# LIN_LIN_52400000h register map
Vendor: Texas Instruments
Peripheral module from a debugger description file (folder AM263P).
Registers are 32-bit, read-write, reset 0x0 unless marked. A register's access mark holds for its fields unless they carry their own. Offsets are as the file gives them; lines under a group give offsets from that group; [hi:lo] are bit positions; {n}, {i} and the like mark numbered series; 'fields as' and 'values as' point back to an identical list; <NAME> marks a mode.

## LIN (part 1 of 2)
0x00 LIN_SCIGCR0 — The SCIGCR0 register defines the module reset.
  [0] RESET — This bit resets the SCI/LIN module. This bit is effective in LIN or SCI-compatible mode.. This bit affects the reset state of the SCI/LIN module. 0 SCI/LIN module is in held in reset.1 SCI/LIN module is out of reset.
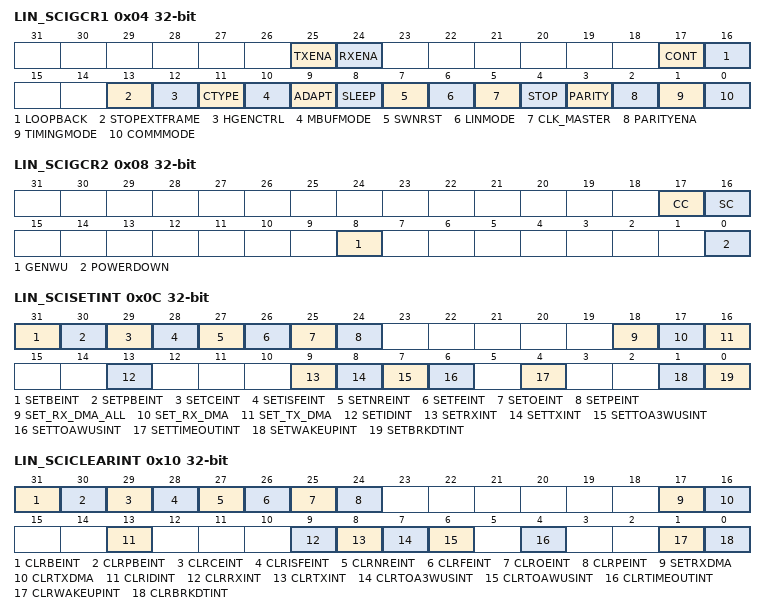
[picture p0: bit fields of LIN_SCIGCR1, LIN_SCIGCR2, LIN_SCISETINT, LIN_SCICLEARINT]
0x04 LIN_SCIGCR1 — The SCIGCR1 register defines the frame format, protocol, and communication mode used by the SCI.
  [25] TXENA — Transmit enable.This bit is effective in LIN and SCI modes. Data is transferred from SCITD or the TDy [with y=0, 1,...7] buffers in LIN mode to the SCITXSHF shift out register only when the TXENA bit is set. Note: Data written to SCITD or the transmit multi-buffer before TXENA is set is nottransmitted. If TXENA is cleared while transmission is ongoing, the data previouslywritten to SCITD is sent [including the checksum byte in LIN mode]. 0 Disable transfers from SCITD or TDy to SCITXSHF1 Enable transfers of data from SCITD or TDy to SCITXSHF
  [24] RXENA — Receive enable.This bit is effective in LIN or SCI-compatible mode. RXENA allows or prevents the transfer of data from SCIRXSHF to SCIRD or the receive multibuffers. Note: Clearing RXENA stops received characters from being transferred into the receive buffer or multi-buffers, prevents the RX status flags [see Table 7] from being updated by receive data, and inhibits both receive and error interrupts. However, the shift register continues to assemble data regardless of the state of RXENA. Note: If RXENA is cleared before the time the reception of a frame is complete, the data from the frame is not transferred into the receive buffer. Note: If RXENA is set before the time the reception of a frame is complete, the data from the frame is transferred into the receive buffer. If RXENA is set while SCIRXSHF is in the process of assembling a frame, the status flags are not guaranteed to be accurate for that frame. To ensure that the status flags correctly reflect what was detected on the bus during a particular frame, RXENA should be set before the detection of that frame 0 Prevents the receiver from transferring data from the shift buffer to the receive buffer or multi-buffers1 Allows the receiver to transfer data from the shift buffer to the receive buffer or multi-buffers
  [17] CONT — Continue on suspend.This bit has an effect only when a program is being debugged with an emulator, and it determines how the SCI/LIN operates when the program is suspended. This bit affects the LIN counters. When this bit is set, the counters are not stopped during debug. When this bit is cleared, the counters are stopped during debug. 0 When debug mode is entered, the SCI/LIN state machine is frozen. Transmissions and LIN counters are halted and resume when debug mode is exited.1 When debug mode is entered, the SCI/LIN continues to operate until the current transmit and receive functions are complete.
  [16] LOOPBACK — Loopback bit.This bit is effective in LIN or SCI-compatible mode. The self-checking option for the SCI/LIN can be selected with this bit. If the LINTX and LINRX pins are configured with SCI/LIN functionality, then the LINTX pin is internally connected to the LINRX pin. Externally, during loop back operation, the LINTX pin outputs a high value and the LINRX pin is in a high-impedance state. If this bit value is changed while the SCI/LIN is transmitting or receiving data, errors may result. 0 Loopback mode is disabled.1 Loopback mode is enabled.
  [13] STOPEXTFRAME — Stop extended frame communication.This bit is effective in LIN mode only. This bit can be written only during extended frame communication. When the extended frame communication is stopped, this bit is cleared automatically. 0 No effect1 Extended frame communication will be stopped, once current frame transmission/reception is completed.
  [12] HGENCTRL — HGEN control bit.This bit is effective in LIN mode only. This bit controls the type of mask filtering comparison. 0 ID filtering using ID-Byte. RECEIVEDID and IDBYTE fields in the LINID register are used for detecting a match (using TX/RXMASK values). Mask of 0xFF in LINMASK register will result in NO match.1 ID filtering using ID-SlaveTask byte (Recommended). RECEIVEDID and IDSLAVETASKBYTE fields in the LINID register are used for detecting a match (using TX/RXMASK values). Mask of 0xFF in LINMASK register will result in ALWAYS match
  [11] CTYPE — Checksum type.This bit is effective in LIN mode only. This bit controls the type of checksum to be used: classic or enhanced. 0 Classic checksum is used. This checksum is compatible with LIN 1.3 slave nodes. The classic checksum contains the modulo-256 sum with carry over all data bytes. Frames sent with Identifier 60 (0x3C) to 63 (0x3F) must allways use the classic checksum.1 Enhanced checksum is used. The enhanced checksum is compatible with LIN 2.0 and newer slave nodes. The enhanced checksum contains the modulo-256 sum with carry over all data bytes AND the protected Identifier.
  [10] MBUFMODE — Multibuffer mode.This bit is effective in LIN or SCI-compatible mode. This bit controls receive/transmit buffer usage, that is, whether the RX/TX multibuffers are used or a single register, RD0/TD0, is used. 0 The multi-buffer mode is disabled.1 The multi-buffer mode is enabled.
  [9] ADAPT — Adapt mode enable.This mode is effective in LIN mode only. This bit has an effect during the detection of the Sync Field. There are two LIN protocol bit rate modes that could be enabled with this bit according to the Node capability file definition: automatic or select. Software and network configuration will decide which of the previous two modes. When this bit is cleared, the LIN 2.0 protocol fixed bit rate should be used. If the ADAPT bit is set, a LIN target node detecting the baudrate will compare it to the prescalers in BRSR register and update it if they are different. The BRSR register will be updated with the new value. If this bit is not set there will be no adjustment to the BRSR register. This field is writable in LIN mode only. 0 Automatic baudrate adjustment is disabled.1 Automatic baudrate adjustment is enabled.
  [8] SLEEP — SCI sleep.SCI compatibility mode only. In a multiprocessor configuration, this bit controls the receive sleep function. Clearing this bit brings the SCI out of sleep mode. The receiver still operates when the SLEEP bit is set; however, RXRDY is updated and SCIRD is loaded with new data only when an address frame is detected. The remaining receiver status flags are updated and an error interrupt is requested if the corresponding interrupt enable bit is set, regardless of the value of the SLEEP bit. In this way, if an error is detected on the receive data line while the SCI is asleep, software can promptly deal with the error condition. The SLEEP bit is not automatically cleared when an address byte is detected. This field is writable in SCI mode only. 0 Sleep mode is disabled.1 Sleep mode is enabled.
  [7] SWNRST — Software reset [active low].This bit is effective in LIN or SCI-compatible mode. The SCI/LIN should only be configured while SWnRST = 0. Only the following configuration bits can be changed in runtime [i.e.,while SWnRESET = 1]:- STOP EXT Frame [SCIGCR1[13]]- CC bit [SCIGCR2[17]]- SC bit [SCIGCR2[16]] 0 The SCI/LIN is in its reset state; no data will be transmitted or received. Writing a 0 to this bit intializes the SCI/LIN state machines and operating flags. All affected logic is held in the reset state until a 1 is written to this bit.1 The SCI/LIN is in its ready state; transmission and reception can occur. After this bit is set to 1, the configuration of the module should not change.
  [6] LINMODE — LIN modeThis bit controls the mode of operation of the module. 0 LIN mode is disabled; SCI compatibility mode is enabled.1 LIN mode is enabled; SCI compatibility mode is disabled.
  [5] CLK_MASTER — SCI internal clock enable or LIN Master/Target configuration.In the SCI mode, this bit enables the clock to the SCI module. In LIN mode, this bit determines whether a LIN node is a target or master. 0 SCI-compatible mode: Reserved.LIN mode: The module is in slave mode.1 SCI-compatible mode: Enable clock to the SCI module.LIN mode: The node is in master mode.
  [4] STOP — SCI number of stop bits.This bit is effective in SCI-compatible mode only. Note: The receiver checks for only one stop bit. However in idle-line mode, the receiver waits until the end of the second stop bit [if STOP = 1] to begin checking for an idle period. This field is writable in SCI mode only. 0 One stop bit is used.1 Two stop bits are used.
  [3] PARITY — SCI parity odd/even selection.This bit is effective in SCI-compatible mode only. If the PARITY ENA bit [SCIGCR1.2] is set, PARITY designates odd or even parity. The parity bit is calculated based on the data bits in each frame and the address bit [in address-bit mode]. The start and stop fields in the frame are not included in the parity calculation. This field is writable in SCI mode only. 0 Odd parity is used. The SCI transmits and expects to receive a value in the parity bit that makes odd the total number of bits in the frame with the value of 1.1 Even parity is used. The SCI transmits and expects to receive a value in the parity bit that makes even the total number of bits in the frame with the value of 1.
  [2] PARITYENA — Parity enable.Enables or disables the parity function. 0 SCI-compatible mode: Parity disabled; no parity bit is generated during transmission or is expected during reception.LIN mode: ID-parity verification is disabled.1 SCI compatible mode: Parity enabled. A parity bit is generated during transmission and is expected during reception.LIN mode: ID-parity verification is enabled.
  [1] TIMINGMODE — SCI timing mode bit.This bit is effective in SCI-compatible mode only. It must be set to 1 when the SCI mode is used. This bit configures the SCI for asynchronous operation. 0 Reserved.1 Must be set to 1 when module is configured for SCI operation
  [0] COMMMODE — SCI/LIN communication mode bit.In compatibility mode, it selects the SCI communication mode. In LIN mode it selects length control option for ID-field bits ID4 and ID5. 0 SCI-compatible mode: Idle-line mode is used.LIN mode: ID4 and ID5 are not used for length control.1 SCI-compatible mode: Address-bit mode is used.LIN mode: ID4 and ID5 are used for length control.
0x08 LIN_SCIGCR2 — The SCIGCR2 register is used to send or compare a checksum byte during extended frames, to generate a wakeup and for low-power mode control of the LIN module.
  [17] CC — Compare Checksum.This mode is effective in LIN mode only. This bit is used by the receiver for extended frames to trigger a checksum compare. The user will initiate this transaction by Writing a one to this bit.In non multibuffer mode, once the CC bit is set, the checksum will be compared on the byte that is currently being received, expected to be the checkbyte.During Multi-buffer mode, following are the scenarios associated with the CC bit :- If CC bit is set during the reception of the data, then the byte that is received after the reception of the programmed no. of data bytes indicated by SCIFORMAT[18:16], is treated as a checksum byte.- If CC bit is set during the IDLE period [i.e. during inter-frame space], then the next immediate byte will be treated as a checksum byte. A CE will immediatly be flagged if there is a checksum error. This bit is automatically cleared once the checksum is successfully compared. 0 No effect1 Compare checksum on expected checkbyte
  [16] SC — Send ChecksumThis mode is effective in LIN mode only. This bit is used by the transmitter with extended frames to send a checkbyte. In non multibuffer mode the checkbyte will be sent after the current byte transmission. In multibuffer mode the checkbyte will be sent after the last byte count, indicated by the SCIFORMAT[18:16]]. This field is writable in LIN mode only. 0 No checkbyte will be sent.1 A checkbyte will be sent. This bit will automatically get cleared after the checkbyte is transmitted. The checksum will not be sent if this bit is set before transmitting the very first byte, that is, during interframe space.
  [8] GENWU — Generate wakeup signal.This bit controls the generation of a wakeup signal, by transmitting the TDO buffer value. This bit is cleared on reception of a valid sync break. 0 No effect1 Transmit TDO for wakeup. This bit will be cleared on a SWnRST (SCIGCR1.7)
  [0] POWERDOWN — Power down.This bit is effective in LIN or SCI-compatible mode. When the powerdown bit is set, the SCI/LIN module attempts to enter local low-power mode. If the POWERDOWN bit is set while the receiver is actively receiving data and the wakeup interrupt is disabled, then the SCI/LIN will delay low-power mode from being entered until completion of reception. In LIN mode the user may set the POWERDOWN bit on Sleep Command reception or on idle bus detection [more than 4 seconds, i.e. 80,000 cycles at 20kHz] 0 Normal operation1 Request local low-power mode
0x0C LIN_SCISETINT access not given — The SCISETINT register is used to enable the various interrupts available in the LIN module.
  [31] SETBEINT — Set bit error interrupt.This bit is effective in LIN mode only. Setting this bit enables the SCI/LIN module to generate an interrupt when there is a bit error. This field is writable in LIN mode only. 0 Interrupt is disabled. Writing a 0 to this bit has no effect.1 Interrupt is enabled. (access R/W1TS)
  [30] SETPBEINT — Set physical bus error interrupt.This bit is effective in LIN mode only. Setting this bit enables the SCI/LIN module to generate an interrupt when a physical bus error occurs. This field is writable in LIN mode only. 0 Interrupt is disabled. Writing a 0 to this bit has no effect.1 Interrupt is enabled. (access R/W1TS)
  [29] SETCEINT — Set checksum-error Interrupt.This bit is effective in LIN mode only. Setting this bit enables the SCI/LIN module to generate an interrupt when there is a checksum error. This field is writable in LIN mode only. 0 Interrupt is disabled. Writing a 0 to this bit has no effect.1 Interrupt is enabled. (access R/W1TS)
  [28] SETISFEINT — Set inconsistent-sync-field-error interrupt.This bit is effective in LIN mode only. Setting this bit enables the SCI/LIN module to generate an interrupt when there is an inconsistent sync field error. This field is writable in LIN mode only. 0 Interrupt is disabled. Writing a 0 to this bit has no effect.1 Interrupt is enabled. (access R/W1TS)
  [27] SETNREINT — Set no-response-error interrupt.This bit is effective in LIN mode only. Setting this bit enables the SCI/LIN module to generate an interrupt when a no-response error occurs. This field is writable in LIN mode only. 0 Interrupt is disabled. Writing a 0 to this bit has no effect.1 Interrupt is enabled. (access R/W1TS)
  [26] SETFEINT — Set framing-error interrupt.This bit is effective in LIN or SCI-compatible mode. Setting this bit enables the SCI/LIN module to generate an interrupt when a framing error occurs. 0 Interrupt is disabled. Writing a 0 to this bit has no effect.1 Interrupt is enabled. (access R/W1TS)
  [25] SETOEINT — Set overrun-error interrupt.This bit is effective in LIN or SCI-compatible mode. Setting this bit enables the SCI/LIN module to generate an interrupt when an overrun error occurs. 0 Interrupt is disabled. Writing a 0 to this bit has no effect.1 Interrupt is enabled. (access R/W1TS)
  [24] SETPEINT — Set parity interrupt.This bit is effective in LIN or SCI-compatible mode. Setting this bit enables the SCI/LIN module to generate an interrupt when a parity error occurs. 0 Interrupt is disabled. Writing a 0 to this bit has no effect.1 Interrupt is enabled. (access R/W1TS)
  [18] SET_RX_DMA_ALL — Set receiver DMA for Address & Data frames.This bit is effective in LIN or SCI-compatible mode. To enable RX DMA request for address and data frames this bit must be set. If it is cleared, RX interrupt request is generated for address frames and DMA requests are generated for data frames. 0 Receiver DMA request is disabled for address frames (RX interrupt request is enabled for address frames). Writing a 0 to this bit has no effect.1 Receiver DMA request is enabled for address and data frames (access R/W1TS)
  [17] SET_RX_DMA — Set receiver DMA.This bit is effective in LIN or SCI-compatible mode. To enable DMA requests for the receiver this bit must be set. If it is cleared, interrupt requests are generated depending on SETRXINT. 0 Receiver DMA request is disabled. Writing a 0 to this bit has no effect.1 Receiver DMA request is enabled. (access R/W1TS)
  [16] SET_TX_DMA — Set transmit DMA.This bit is effective in LIN or SCI-compatible mode. To enable DMA requests for the transmitter, this bit must be set. If it is cleared, interrupt requests are generated depending on SETTXINT. 0 Transmit DMA request is disabled. Writing a 0 to this bit has no effect.1 Transmit DMA request is enabled (access R/W1TS)
  [13] SETIDINT — Set Identification interrupt.This bit is effective in LIN mode only. This bit is set to enable interrupt once a valid matching identifier is received. 0 Interrupt is disabled. Writing a 0 to this bit has no effect.1 Interrupt is enabled. (access R/W1TS)
  [9] SETRXINT — Set Receiver interrupt.Setting this bit enables the SCI/LIN to generate a receive interrupt after a frame has been completely received and the data is being transferred from SCIRXSHF to SCIRD. 0 Interrupt is disabled. Writing a 0 to this bit has no effect.1 Interrupt is enabled. (access R/W1TS)
  [8] SETTXINT — Set Transmitter interrupt.Setting this bit enables the SCI/LIN to generate a transmit interrupt as data is being transferred from SCITD to SCITXSHF and the TXRDY bit is being set. 0 Interrupt is disabled. Writing a 0 to this bit has no effect.1 Interrupt is enabled. (access R/W1TS)
  [7] SETTOA3WUSINT — Set Timeout After 3 Wakeup Signals interrupt.This bit is effective in LIN mode only. Setting this bit enables the SCI/LIN to generate an interrupt when there is a timeout after 3 wakeup signals have been sent. This field is writable in LIN mode only. 0 Interrupt is disabled. Writing a 0 to this bit has no effect.1 Interrupt is enabled. (access R/W1TS)
  [6] SETTOAWUSINT — Set Timeout After Wakeup Signal interrupt.This bit is effective in LIN mode only. Setting this bit enables the SCI/LIN to generate an interrupt when there is a timeout after one wakeup signal has been sent. This field is writable in LIN mode only. 0 Interrupt is disabled. Writing a 0 to this bit has no effect.1 Interrupt is enabled. (access R/W1TS)
  [4] SETTIMEOUTINT — Set timeout interrupt.This bit is effective in LIN mode only. Setting this bit enables the SCI/LIN to generate an interrupt when no LIN bus activity [bus idle] occurs for at least 4 seconds. This field is writable in LIN mode only. 0 Interrupt is disabled. Writing a 0 to this bit has no effect.1 Interrupt is enabled. (access R/W1TS)
  [1] SETWAKEUPINT — Set wake-up interrupt.This bit is effective in LIN or SCI-compatible mode. Setting this bit enables the SCI/LIN to generate a wake-up interrupt and thereby exit low-power mode. The wake-up interrupt is asserted on falling edge of the wake-up pulse. If enabled, the wake-up interrupt is asserted when local low-power mode is requested while the receiver is busy or if a low level is detected on the SCIRX pin during low-power mode. Wake-up interrupt is not asserted upon a wakeup pulse if the module is not in power down mode. 0 Interrupt is disabled. Writing a 0 to this bit has no effect.1 Interrupt is enabled. (access R/W1TS)
  [0] SETBRKDTINT — Set break-detect interrupt.This bit is effective in SCI-compatible mode only. Setting this bit enables the SCI/LIN to generate an interrupt if a break condition is detected on the LINRX pin. This field is writable in SCI mode only. 0 Interrupt is disabled. Writing a 0 to this bit has no effect.1 Interrupt is enabled. (access R/W1TS)
0x10 LIN_SCICLEARINT access not given — The SCICLEARINT register is used to disable the enabled interrupts without accessing the SCISETINT register.
  [31] CLRBEINT — Clear Bit Error Interrupt.This bit is effective in LIN mode only. Setting this bit disables the bit error interrupt. This field is writable in LIN mode only. 0 Interrupt is disabled. Writing a 0 to this bit has no effect.1 Interrupt is enabled. Writing a 1 to this bit will disable the interrupt and clear this bit. (access R/W1TC)
  [30] CLRPBEINT — Clear Physical Bus Error Interrupt.This bit is effective in LIN mode only. Setting this bit disables the physical-bus error interrupt. This field is writable in LIN mode only. 0 Interrupt is disabled. Writing a 0 to this bit has no effect.1 Interrupt is enabled. Writing a 1 to this bit will disable the interrupt and clear this bit. (access R/W1TC)
  [29] CLRCEINT — Clear checksum-error Interrupt.This bit is effective in LIN mode only. Setting this bit disables the checksum-error interrupt. This field is writable in LIN mode only. 0 Interrupt is disabled. Writing a 0 to this bit has no effect.1 Interrupt is enabled. Writing a 1 to this bit will disable the interrupt and clear this bit. (access R/W1TC)
  [28] CLRISFEINT — Clear Inconsistent-Sync-Field-Error Interrupt.This bit is effective in LIN mode only. Setting this bit disables the ISFE interrupt. This field is writable in LIN mode only. 0 Interrupt is disabled. Writing a 0 to this bit has no effect.1 Interrupt is enabled. Writing a 1 to this bit will disable the interrupt and clear this bit. (access R/W1TC)
  [27] CLRNREINT — Clear No-Reponse-Error Interrupt.This bit is effective in LIN mode only. Setting this bit disables the no-response error interrupt. This field is writable in LIN mode only. 0 Interrupt is disabled. Writing a 0 to this bit has no effect.1 Interrupt is enabled. Writing a 1 to this bit will disable the interrupt and clear this bit. (access R/W1TC)
  [26] CLRFEINT — Clear Framing-Error Interrupt.This bit is effective in LIN or SCI-compatible mode. Setting this bit disables framing-error interrupt. 0 Interrupt is disabled. Writing a 0 to this bit has no effect.1 Interrupt is enabled. Writing a 1 to this bit will disable the interrupt and clear this bit. (access R/W1TC)
  [25] CLROEINT — Clear Overrun-Error Interrupt.This bit is effective in LIN or SCI-compatible mode. Setting this bit disables the overrun interrupt. 0 Interrupt is disabled. Writing a 0 to this bit has no effect.1 Interrupt is enabled. Writing a 1 to this bit will disable the interrupt and clear this bit. (access R/W1TC)
  [24] CLRPEINT — Clear Parity Interrupt.This bit is effective in LIN or SCI-compatible mode. Setting this bit disables the parity error interrupt. 0 Interrupt is disabled. Writing a 0 to this bit has no effect.1 Interrupt is enabled. Writing a 1 to this bit will disable the interrupt and clear this bit. (access R/W1TC)
  [17] SETRXDMA — Clear receiver DMA.This bit is effective in LIN or SCI-compatible mode. Setting this bit disables the receive DMA request. 0 Receiver DMA request is disabled. Writing a 0 to this bit has no effect.1 Receiver DMA request is enabled. Writing a 1 to this bit will disable the DMA request and clear this bit. (access R/W1TC)
  [16] CLRTXDMA — Clear transmit DMA.This bit is effective in LIN or SCI-compatible mode. Setting this bit disables the transmit DMA request. 0 Transmit DMA request is disabled. Writing a 0 to this bit has no effect.1 Transmit DMA request is enabled. Writing a 1 to this bit will disable the DMA request and clear this bit. (access R/W1TC)
  [13] CLRIDINT — Clear Identifier interrupt.This bit is effective in LIN mode only. Setting this bit disables the ID interrupt. 0 Interrupt is disabled. Writing a 0 to this bit has no effect.1 Interrupt is enabled. Writing a 1 to this bit will disable the interrupt and clear this bit. (access R/W1TC)
  [9] CLRRXINT — Clear Receiver interrupt.This bit is effective in LIN or SCI-compatible mode. Setting this bit disables the receiver interrupt. 0 Interrupt is disabled. Writing a 0 to this bit has no effect.1 Interrupt is enabled. Writing a 1 to this bit will disable the interrupt and clear this bit. (access R/W1TC)
  [8] CLRTXINT — Clear Transmitter interrupt.This bit is effective in LIN or SCI-compatible mode. Setting this bit disables the transmitter interrupt. 0 Interrupt is disabled. Writing a 0 to this bit has no effect.1 Interrupt is enabled. Writing a 1 to this bit will disable the interrupt and clear this bit. (access R/W1TC)
  [7] CLRTOA3WUSINT — Clear Timeout After 3 Wakeup Signals interrupt.This bit is effective in LIN mode only. Setting this bit disables the timeout after 3 wakeup signals interrupt. This field is writable in LIN mode only. 0 Interrupt is disabled. Writing a 0 to this bit has no effect.1 Interrupt is enabled. Writing a 1 to this bit will disable the interrupt and clear this bit. (access R/W1TC)
  [6] CLRTOAWUSINT — Clear Timeout After Wakeup Signal interrupt.This bit is effective in LIN mode only. Setting this bit disables the timeout after one wakeup signal interrupt. This field is writable in LIN mode only. 0 Interrupt is disabled. Writing a 0 to this bit has no effect.1 Interrupt is enabled. Writing a 1 to this bit will disable the interrupt and clear this bit. (access R/W1TC)
  [4] CLRTIMEOUTINT — Clear Timeout interrupt.This bit is effective in LIN mode only. Setting this bit disables the timeout [LIN bus idle] interrupt. This field is writable in LIN mode only. 0 Interrupt is disabled. Writing a 0 to this bit has no effect.1 Interrupt is enabled. Writing a 1 to this bit will disable the interrupt and clear this bit. (access R/W1TC)
  [1] CLRWAKEUPINT — Clear Wake-up interrupt.This bit is effective in LIN or SCI-compatible mode. Setting this bit disables the wake-up interrupt. 0 Interrupt is disabled. Writing a 0 to this bit has no effect.1 Interrupt is enabled. Writing a 1 to this bit will disable the interrupt and clear this bit. (access R/W1TC)
  [0] CLRBRKDTINT — Clear Break-detect interrupt.This bit is effective in SCI-compatible mode only. Setting this bit disables the Break-detect interrupt. This field is writable in SCI mode only. 0 Interrupt is disabled. Writing a 0 to this bit has no effect.1 Interrupt is enabled. Writing a 1 to this bit will disable the interrupt and clear this bit. (access R/W1TC)
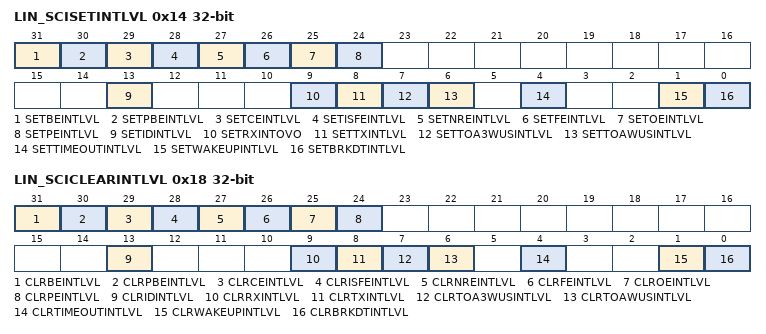
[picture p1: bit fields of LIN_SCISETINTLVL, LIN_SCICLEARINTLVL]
0x14 LIN_SCISETINTLVL access not given — The SCISETINTLVL register is used to map individual interrupt sources to the INT1 interrupt line.
  [31] SETBEINTLVL — Set Bit Error interrupt level.This bit is effective in LIN mode only. Writing to this bit maps the Bit Error interrupt level to the INT1 line. This field is writable in LIN mode only. 0 Interrupt level mapped to INT0 line.1 Interrupt level mapped to INT1 line. (access R/W1TS)
  [30] SETPBEINTLVL — Set Physical Bus Error interrupt level.This bit is effective in LIN mode only. Writing to this bit maps the Physical Bus Error interrupt level to the INT1 line. This field is writable in LIN mode only. 0 Interrupt level mapped to INT0 line.1 Interrupt level mapped to INT1 line. (access R/W1TS)
  [29] SETCEINTLVL — Set Checksum-error interrupt level.This bit is effective in LIN mode only. Writing to this bit maps the Checksum-error interrupt level to the INT1 line. This field is writable in LIN mode only. 0 Interrupt level mapped to INT0 line.1 Interrupt level mapped to INT1 line. (access R/W1TS)
  [28] SETISFEINTLVL — Set Inconsistent-Sync-Field-Error interrupt level.This bit is effective in LIN mode only. Writing to this bit maps the Inconsistent-Sync-Field-Error interrupt level to the INT1 line. This field is writable in LIN mode only. 0 Interrupt level mapped to INT0 line.1 Interrupt level mapped to INT1 line. (access R/W1TS)
  [27] SETNREINTLVL — Set No-Reponse-Error interrupt level.This bit is effective in LIN mode only. Writing to this bit maps the No-Response-Error interrupt level to the INT1 line. This field is writable in LIN mode only. 0 Interrupt level mapped to INT0 line.1 Interrupt level mapped to INT1 line. (access R/W1TS)
  [26] SETFEINTLVL — Set Framing-Error interrupt level.This bit is effective in LIN or SCI-compatible mode. Writing to this bit maps the Framing-Error interrupt level to the INT1 line. 0 Interrupt level mapped to INT0 line.1 Interrupt level mapped to INT1 line. (access R/W1TS)
  [25] SETOEINTLVL — Set Overrun-Error Interrupt Level.This bit is effective in LIN or SCI-compatible mode. Writing to this bit maps the Overrun-Error interrupt level to the INT1 line. 0 Interrupt level mapped to INT0 line.1 Interrupt level mapped to INT1 line. (access R/W1TS)
  [24] SETPEINTLVL — Set Parity Error interrupt level.This bit is effective in LIN or SCI-compatible mode. Writing to this bit maps the Parity error interrupt level to the INT1 line. 0 Interrupt level mapped to INT0 line.1 Interrupt level mapped to INT1 line. (access R/W1TS)
  [13] SETIDINTLVL — Set ID interrupt level.This bit is effective in LIN mode only. Writing to this bit maps the ID interrupt level to the INT1 line. This field is writable in LIN mode only. 0 Interrupt level mapped to INT0 line.1 Interrupt level mapped to INT1 line. (access R/W1TS)
  [9] SETRXINTOVO — Set Receiver interrupt level.This bit is effective in LIN or SCI-compatible mode. Writing to this bit maps the receiver interrupt level to the INT1 line. 0 Interrupt level mapped to INT0 line.1 Interrupt level mapped to INT1 line. (access R/W1TS)
  [8] SETTXINTLVL — Set Transmitter interrupt level.This bit is effective in LIN or SCI-compatible mode. Writing to this bit maps the transmitter interrupt level to the INT1 line. 0 Interrupt level mapped to INT0 line.1 Interrupt level mapped to INT1 line. (access R/W1TS)
  [7] SETTOA3WUSINTLVL — Set Timeout After 3 Wakeup Signals interrupt level.This bit is effective in LIN mode only. Writing to this bit maps the timeout after 3 wakeup signals interrupt level to the INT1 line. This field is writable in LIN mode only. 0 Interrupt level mapped to INT0 line.1 Interrupt level mapped to INT1 line. (access R/W1TS)
  [6] SETTOAWUSINTLVL — Set Timeout After Wakeup Signal interrupt level.This bit is effective in LIN mode only. Writing to this bit maps the the timeout after wakeup interrupt level to the INT1 line. This field is writable in LIN mode only. 0 Interrupt level mapped to INT0 line.1 Interrupt level mapped to INT1 line. (access R/W1TS)
  [4] SETTIMEOUTINTLVL — Set Timeout interrupt level.This bit is effective in LIN mode only. Writing to this bit maps the timeout interrupt level to the INT1 line. This field is writable in LIN mode only. 0 Interrupt level mapped to INT0 line.1 Interrupt level mapped to INT1 line. (access R/W1TS)
  [1] SETWAKEUPINTLVL — Set Wake-up interrupt level.This bit is effective in LIN or SCI-compatible mode. Writing to this bit maps the Wake-up interrupt level to the INT1 line. 0 Interrupt level mapped to INT0 line.1 Interrupt level mapped to INT1 line. (access R/W1TS)
  [0] SETBRKDTINTLVL — Set Break-detect interrupt level.This bit is effective in SCI-compatible mode only. Writing to this bit maps the Break-detect interrupt level to the INT1 line. This field is writable in SCI mode only. 0 Interrupt level mapped to INT0 line.1 Interrupt level mapped to INT1 line. (access R/W1TS)
0x18 LIN_SCICLEARINTLVL access not given — The SCICLEARINTLVL register is used to map individual interrupt sources to the INT0 line.
  [31] CLRBEINTLVL — Clear Bit Error interrupt level.This bit is effective in LIN mode only. Writing to this bit maps the Bit Error interrupt level to the INT0 line. This field is writable in LIN mode only. 0 Interrupt level mapped to INT0 line.1 Interrupt level mapped to INT1 line. Writing a 1 to this bit will map the interrupt to INT0 and clear this bit. (access R/W1TC)
  [30] CLRPBEINTLVL — Clear Physical Bus Error interrupt level.This bit is effective in LIN mode only. Writing to this bit maps the Physical Bus Error interrupt level to the INT0 line. This field is writable in LIN mode only. 0 Interrupt level mapped to INT0 line.1 Interrupt level mapped to INT1 line. Writing a 1 to this bit will map the interrupt to INT0 and clear this bit. (access R/W1TC)
  [29] CLRCEINTLVL — Clear Checksum-error interrupt level.This bit is effective in LIN mode only. Writing to this bit maps the Checksum-error interrupt level to the INT0 line. This field is writable in LIN mode only. 0 Interrupt level mapped to INT0 line.1 Interrupt level mapped to INT1 line. Writing a 1 to this bit will map the interrupt to INT0 and clear this bit. (access R/W1TC)
  [28] CLRISFEINTLVL — Clear Inconsistent-Sync-Field-Error interrupt level.This bit is effective in LIN mode only. Writing to this bit maps the Inconsistent-Sync-Field-Error interrupt level to the INT0 line. This field is writable in LIN mode only. 0 Interrupt level mapped to INT0 line.1 Interrupt level mapped to INT1 line. Writing a 1 to this bit will map the interrupt to INT0 and clear this bit. (access R/W1TC)
  [27] CLRNREINTLVL — Clear No-Reponse-Error interrupt level.This bit is effective in LIN mode only. Writing to this bit maps the No-Response-Error interrupt level to the INT0 line. This field is writable in LIN mode only. 0 Interrupt level mapped to INT0 line.1 Interrupt level mapped to INT1 line. Writing a 1 to this bit will map the interrupt to INT0 and clear this bit. (access R/W1TC)
  [26] CLRFEINTLVL — Clear Framing-Error interrupt level.This bit is effective in LIN or SCI-compatible mode. Writing to this bit maps the Framing-Error interrupt level to the INT0 line. 0 Interrupt level mapped to INT0 line.1 Interrupt level mapped to INT1 line. Writing a 1 to this bit will map the interrupt to INT0 and clear this bit. (access R/W1TC)
  [25] CLROEINTLVL — Clear Overrun-Error Interrupt Level.This bit is effective in LIN or SCI-compatible mode. Writing to this bit maps the Overrun-Error interrupt level to the INT0 line. 0 Interrupt level mapped to INT0 line.1 Interrupt level mapped to INT1 line. Writing a 1 to this bit will map the interrupt to INT0 and clear this bit. (access R/W1TC)
  [24] CLRPEINTLVL — Clear Parity Error interrupt level.This bit is effective in LIN or SCI-compatible mode. Writing to this bit maps the Parity Error interrupt level to the INT0 line. 0 Interrupt level mapped to INT0 line.1 Interrupt level mapped to INT1 line. Writing a 1 to this bit will map the interrupt to INT0 and clear this bit. (access R/W1TC)
  [13] CLRIDINTLVL — Clear ID interrupt level.This bit is effective in LIN mode only. Writing to this bit maps the ID interrupt level to the INT0 line. This field is writable in LIN mode only. 0 Interrupt level mapped to INT0 line.1 Interrupt level mapped to INT1 line. Writing a 1 to this bit will map the interrupt to INT0 and clear this bit. (access R/W1TC)
  [9] CLRRXINTLVL — Clear Receiver interrupt level.This bit is effective in LIN or SCI-compatible mode. Writing to this bit maps the receiver interrupt level to the INT0 line. 0 Interrupt level mapped to INT0 line.1 Interrupt level mapped to INT1 line. Writing a 1 to this bit will map the interrupt to INT0 and clear this bit. (access R/W1TC)
  [8] CLRTXINTLVL — Clear Transmitter interrupt level.This bit is effective in LIN or SCI-compatible mode. Writing to this bit maps the transmitter interrupt level to the INT0 line. 0 Interrupt level mapped to INT0 line.1 Interrupt level mapped to INT1 line. Writing a 1 to this bit will map the interrupt to INT0 and clear this bit. (access R/W1TC)
  [7] CLRTOA3WUSINTLVL — Clear Timeout After 3 Wakeup Signals interrupt level.This bit is effective in LIN mode only. Writing to this bit maps the timeout after 3 wakeup signals interrupt level to the INT0 line. This field is writable in LIN mode only. 0 Interrupt level mapped to INT0 line.1 Interrupt level mapped to INT1 line. Writing a 1 to this bit will map the interrupt to INT0 and clear this bit. (access R/W1TC)
  [6] CLRTOAWUSINTLVL — Clear Timeout After Wakeup Signal interrupt level.This bit is effective in LIN mode only. Writing to this bit maps the the timeout after wakeup interrupt level to the INT0 line. This field is writable in LIN mode only. 0 Interrupt level mapped to INT0 line.1 Interrupt level mapped to INT1 line. Writing a 1 to this bit will map the interrupt to INT0 and clear this bit. (access R/W1TC)
  [4] CLRTIMEOUTINTLVL — Clear Timeout interrupt level.This bit is effective in LIN mode only. Writing to this bit maps the timeout interrupt level to the INT0 line. This field is writable in LIN mode only. 0 Interrupt level mapped to INT0 line.1 Interrupt level mapped to INT1 line. Writing a 1 to this bit will map the interrupt to INT0 and clear this bit. (access R/W1TC)
  [1] CLRWAKEUPINTLVL — Clear Wake-up interrupt level.This bit is effective in LIN or SCI-compatible mode. Writing to this bit maps the Wake-up interrupt level to the INT0 line. 0 Interrupt level mapped to INT0 line. Writing a 0 to this bit has no effect.1 Interrupt level mapped to INT1 line. Writing a 1 to this bit will map the interrupt to INT0 and clear this bit. (access R/W1TC)
  [0] CLRBRKDTINTLVL — Clear Break-detect interrupt level.This bit is effective in SCI-compatible mode only. Writing to this bit maps the Break-detect interrupt level to the INT0 line. This field is writable in SCI mode only. 0 Interrupt level mapped to INT0 line.1 Interrupt level mapped to INT1 line. Writing a 1 to this bit will map the interrupt to INT0 and clear this bit. (access R/W1TC)
